# NAVSS0_BCDMA_0_CRED register map
Vendor: Texas Instruments
Peripheral module from a debugger description file (folder J721S2).
Registers are 32-bit, read-write, reset 0x0 unless marked. A register's access mark holds for its fields unless they carry their own. Offsets are as the file gives them; lines under a group give offsets from that group; [hi:lo] are bit positions; {n}, {i} and the like mark numbered series; 'fields as' and 'values as' point back to an identical list; <NAME> marks a mode.

## NAVSS0_BCDMA_0_CRED
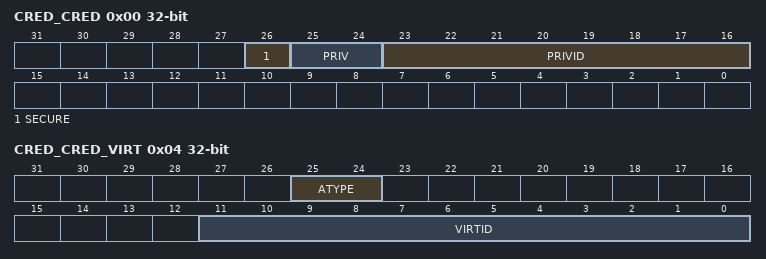
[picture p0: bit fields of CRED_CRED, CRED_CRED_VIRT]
0x00 CRED_CRED — The Credentials Register provides credentials to be used when performing memory accesses using this flow.
  [26] SECURE — Secure attribute
  [25:24] PRIV — Privelege attribute
  [23:16] PRIVID — Privelege ID attribute
0x04 CRED_CRED_VIRT — The Credentials Virtual Register provides virtual credentials to be used when performing memory accesses using this flow to the ring or descriptors.
  [25:24] ATYPE — This field controls how pointers will be interpreted for Ring Accelerator accesses on this channel. The values are encoded as follows: 0 = Pointers are physical addresses 1 = Pointers are intermediate addresses which require intermediate to physical transaction before they can be decoded 2 = Pointers are virtual addresses which require virtual to physical translation before they can be decoded. All transactions from this channel which are destined to the Ring Accelerator will have the mem*_catype attribute set equal to the value given in this register field.
  [11:0] VIRTID
